# CY8C5888LTI_LP097 register map
File version: 0.1
CY8C58LP
Registers are 8-bit, read-write, no defined reset value unless marked. A register's access mark holds for its fields unless they carry their own. Offsets are from the block's base; lines under a group give offsets from that group; [hi:lo] are bit positions; {n}, {i} and the like mark numbered series; 'fields as' and 'values as' point back to an identical list; <NAME> marks a mode.

## Memory map
0x00000000 Timer1
0x00000000 Timer2_Reset
0x00000000 Timer2
0x00000000 Timer1_Reset
0x00000000 UART_GPS — UART
0x00000000 UART_VMON — UART
0x00000000 UART_DEBUG — UART

## Timer1
Base 0x00000000
0x40006403 Timer1_COUNTER 16-bit — UDB.A0 - Current Counter Value
0x40006423 Timer1_PERIOD 16-bit — UDB.D0 - Assigned Period
0x40006433 Timer1_COMPARE 16-bit — UDB.D1 - Assigned Compare Value
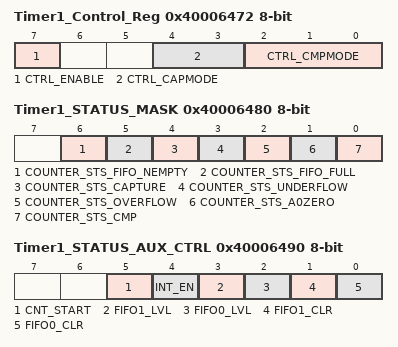
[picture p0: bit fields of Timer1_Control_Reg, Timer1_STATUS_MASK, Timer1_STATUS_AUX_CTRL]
0x40006472 Timer1_Control_Reg — UDB Control Register - Assigned Control Register Value
  [7] CTRL_ENABLE — Enable Counter
  [4:3] CTRL_CAPMODE — Capture mode
  [2:0] CTRL_CMPMODE — Compare mode
0x40006480 Timer1_STATUS_MASK — UDB Status bits Interrupt Mask Enable Register
  [6] COUNTER_STS_FIFO_NEMPTY — FIFO Not Empty Status
  [5] COUNTER_STS_FIFO_FULL — FIFO Full Status
  [4] COUNTER_STS_CAPTURE — Capture Status
  [3] COUNTER_STS_UNDERFLOW — Underflow status
  [2] COUNTER_STS_OVERFLOW — Overflow status
  [1] COUNTER_STS_A0ZERO — A0 Zero ouput status
  [0] COUNTER_STS_CMP — Compare output status
0x40006490 Timer1_STATUS_AUX_CTRL — UDB Auxilliary Control Register
  [5] CNT_START — FIFO0 clear
    0=E_CNT_START0 (Disable counter); 1=E_CNT_START1 (Enable counter)
  [4] INT_EN
    0=E_INT_EN0 (Interrupt disabled); 1=E_INT_EN1 (Interrupt enabled)
  [3] FIFO1_LVL — FIFO level
    0=E_FIFO_LVL_0 (FIFO LVL: input mode: FIFO not full; output mode: FIFO not empty); 1=E_FIFO_LVL_1 (FIFO LVL: input mode: FIFO at least 1/2 empty; output mode: FIFO at least 1/2 full)
  [2] FIFO0_LVL — FIFO level
    values as FIFO1_LVL
  [1] FIFO1_CLR — FIFO1 clear
    0=E_FIFO_CLR_0 (Normal FIFO operation); 1=E_FIFO_CLR_1 (Clear FIFO state)
  [0] FIFO0_CLR — FIFO0 clear
    values as FIFO1_CLR

## Timer2_Reset
Base 0x00000000
0x40006473 Timer2_Reset_CONTROL_REG

## Timer2
Base 0x00000000
0x40006405 Timer2_COUNTER 16-bit — UDB.A0 - Current Counter Value
0x40006425 Timer2_PERIOD 16-bit — UDB.D0 - Assigned Period
0x40006435 Timer2_COMPARE 16-bit — UDB.D1 - Assigned Compare Value
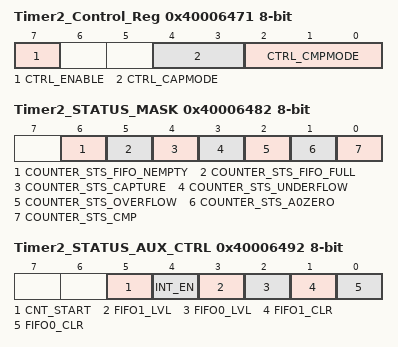
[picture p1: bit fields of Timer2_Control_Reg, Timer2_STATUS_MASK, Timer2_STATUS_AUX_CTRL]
0x40006471 Timer2_Control_Reg — UDB Control Register - Assigned Control Register Value
  [7] CTRL_ENABLE — Enable Counter
  [4:3] CTRL_CAPMODE — Capture mode
  [2:0] CTRL_CMPMODE — Compare mode
0x40006482 Timer2_STATUS_MASK — UDB Status bits Interrupt Mask Enable Register
  fields as Timer1.Timer1_STATUS_MASK
0x40006492 Timer2_STATUS_AUX_CTRL — UDB Auxilliary Control Register
  fields as Timer1.Timer1_STATUS_AUX_CTRL

## Timer1_Reset
Base 0x00000000
0x40006470 Timer1_Reset_CONTROL_REG

## UART_GPS — UART
Base 0x00000000
0x40006429 RX_UART_GPS_RX_ADDRESS1 — RX Address1 Register
0x40006439 RX_UART_GPS_RX_ADDRESS2 — RX Address2 Register
0x40006440 TX_UART_GPS_TX_DATA — TX Data Register
0x40006449 RX_UART_GPS_RX_DATA — RX Data Register
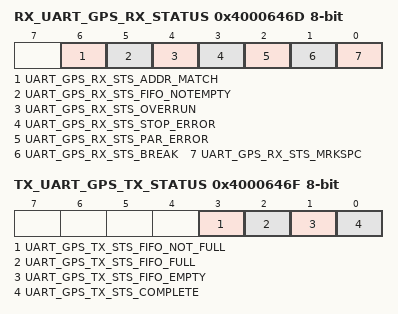
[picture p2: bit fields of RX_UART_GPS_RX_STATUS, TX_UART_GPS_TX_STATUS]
0x4000646D RX_UART_GPS_RX_STATUS — RX status register
  [6] UART_GPS_RX_STS_ADDR_MATCH ro, [5] UART_GPS_RX_STS_FIFO_NOTEMPTY ro, [4] UART_GPS_RX_STS_OVERRUN ro, [3] UART_GPS_RX_STS_STOP_ERROR ro, [2] UART_GPS_RX_STS_PAR_ERROR ro, [1] UART_GPS_RX_STS_BREAK ro, [0] UART_GPS_RX_STS_MRKSPC ro
0x4000646F TX_UART_GPS_TX_STATUS — TX status register
  [3] UART_GPS_TX_STS_FIFO_NOT_FULL ro, [2] UART_GPS_TX_STS_FIFO_FULL ro, [1] UART_GPS_TX_STS_FIFO_EMPTY ro, [0] UART_GPS_TX_STS_COMPLETE ro

## UART_VMON — UART
Base 0x00000000
0x4000644E TX_UART_VMON_TX_DATA — TX Data Register
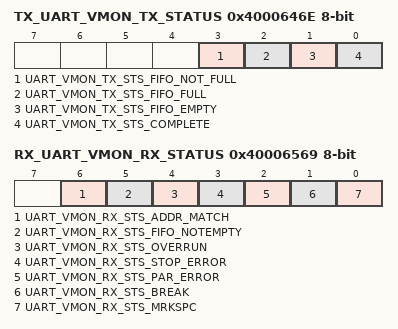
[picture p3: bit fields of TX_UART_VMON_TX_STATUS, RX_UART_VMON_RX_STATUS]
0x4000646E TX_UART_VMON_TX_STATUS — TX status register
  [3] UART_VMON_TX_STS_FIFO_NOT_FULL ro, [2] UART_VMON_TX_STS_FIFO_FULL ro, [1] UART_VMON_TX_STS_FIFO_EMPTY ro, [0] UART_VMON_TX_STS_COMPLETE ro
0x4000652A RX_UART_VMON_RX_ADDRESS1 — RX Address1 Register
0x4000653A RX_UART_VMON_RX_ADDRESS2 — RX Address2 Register
0x4000654A RX_UART_VMON_RX_DATA — RX Data Register
0x40006569 RX_UART_VMON_RX_STATUS — RX status register
  [6] UART_VMON_RX_STS_ADDR_MATCH ro, [5] UART_VMON_RX_STS_FIFO_NOTEMPTY ro, [4] UART_VMON_RX_STS_OVERRUN ro, [3] UART_VMON_RX_STS_STOP_ERROR ro, [2] UART_VMON_RX_STS_PAR_ERROR ro, [1] UART_VMON_RX_STS_BREAK ro, [0] UART_VMON_RX_STS_MRKSPC ro

## UART_DEBUG — UART
Base 0x00000000
0x4000644C TX_UART_DEBUG_TX_DATA — TX Data Register
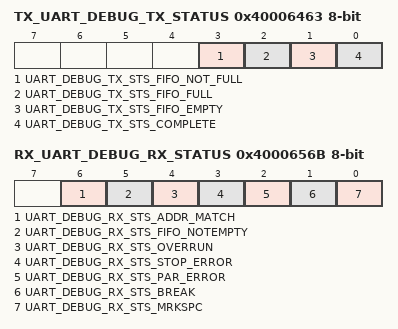
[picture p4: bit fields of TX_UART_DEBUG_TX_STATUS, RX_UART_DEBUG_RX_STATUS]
0x40006463 TX_UART_DEBUG_TX_STATUS — TX status register
  [3] UART_DEBUG_TX_STS_FIFO_NOT_FULL ro, [2] UART_DEBUG_TX_STS_FIFO_FULL ro, [1] UART_DEBUG_TX_STS_FIFO_EMPTY ro, [0] UART_DEBUG_TX_STS_COMPLETE ro
0x40006528 RX_UART_DEBUG_RX_ADDRESS1 — RX Address1 Register
0x40006538 RX_UART_DEBUG_RX_ADDRESS2 — RX Address2 Register
0x40006548 RX_UART_DEBUG_RX_DATA — RX Data Register
0x4000656B RX_UART_DEBUG_RX_STATUS — RX status register
  [6] UART_DEBUG_RX_STS_ADDR_MATCH ro, [5] UART_DEBUG_RX_STS_FIFO_NOTEMPTY ro, [4] UART_DEBUG_RX_STS_OVERRUN ro, [3] UART_DEBUG_RX_STS_STOP_ERROR ro, [2] UART_DEBUG_RX_STS_PAR_ERROR ro, [1] UART_DEBUG_RX_STS_BREAK ro, [0] UART_DEBUG_RX_STS_MRKSPC ro
